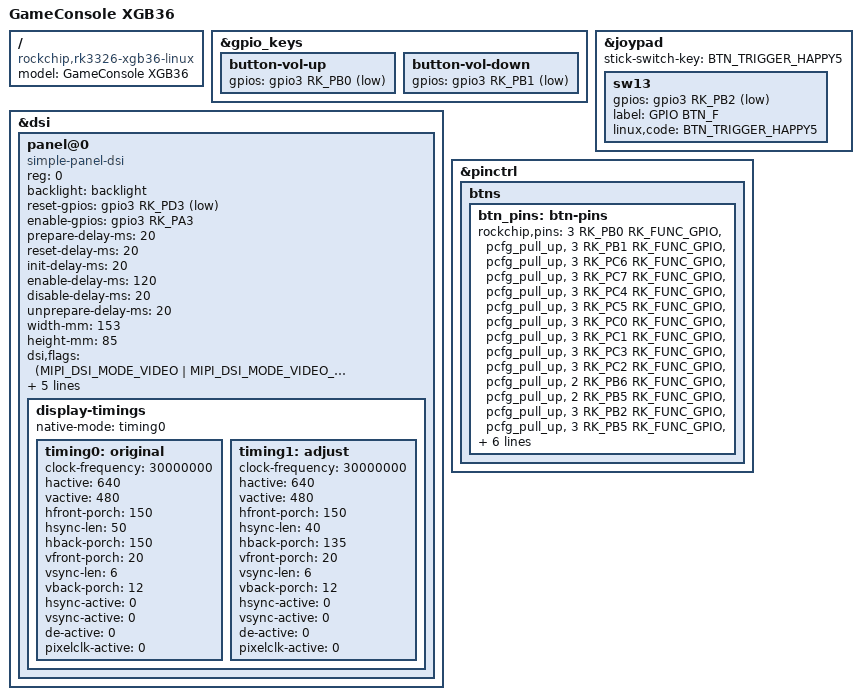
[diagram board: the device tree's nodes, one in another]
// SPDX-License-Identifier: (GPL-2.0+ OR MIT)
/*
* Copyright (c) 2025 kk&lcdyk
*
* GameConsole XGB36
*
*/

/dts-v1/;
#include "rk3326-mymini-linux.dts"

/ {
	model = "GameConsole XGB36";
	compatible = "rockchip,rk3326-xgb36-linux", "rockchip,rk3326";
};

&gpio_keys {
    button-vol-up {
        gpios = <&gpio3 RK_PB0 GPIO_ACTIVE_LOW>;
    };
    button-vol-down {
        gpios = <&gpio3 RK_PB1 GPIO_ACTIVE_LOW>;
    };
};

&joypad {
	stick-switch-key = <BTN_TRIGGER_HAPPY5>;
	sw13 {
		gpios = <&gpio3 RK_PB2 GPIO_ACTIVE_LOW>;
		label = "GPIO BTN_F";
		linux,code = <BTN_TRIGGER_HAPPY5>;
	};
};

&dsi {
	status = "okay";
	
	panel@0 {
		compatible = "simple-panel-dsi";
		reg = <0>;
		/* pwm1 backlight */
		backlight = <&backlight>;
		/* LCD reset gpio GPIO3.D3 */
		reset-gpios = <&gpio3 RK_PD3 GPIO_ACTIVE_LOW>;
		/* power-supply-gpio GPIO3.A3  */
		enable-gpios = <&gpio3 RK_PA3 GPIO_ACTIVE_HIGH>;
		prepare-delay-ms = <20>;
		reset-delay-ms = <20>;
		init-delay-ms = <20>;
		enable-delay-ms = <120>;
		disable-delay-ms = <20>;
		unprepare-delay-ms = <20>;
		width-mm = <153>;
		height-mm = <85>;
		dsi,flags  = <(MIPI_DSI_MODE_VIDEO |
		MIPI_DSI_MODE_VIDEO_BURST |
		MIPI_DSI_MODE_LPM |
		MIPI_DSI_MODE_EOT_PACKET)>;
		dsi,format = <MIPI_DSI_FMT_RGB888>;
		dsi,lanes = <4>;
		panel-init-sequence = [39 00 04 b9 f1 12 83 39 00 06 b1 00 00 00 da 80 39 00 04 b2 00 13 70 39 00 0b b3 10 10 28 28 03 ff 00 00 00 00 15 00 02 b4 80 15 00 03 b5 0a 0a 15 00 03 b6 82 82 39 00 05 b8 26 62 f0 63 39 00 1c ba 33 81 05 f9 0e 0e 20 00 00 00 00 00 00 00 44 25 00 90 0a 00 00 01 4f 01 00 00 37 15 00 02 bc 47 39 00 04 bf 02 11 00 39 00 0a c0 73 73 50 50 00 00 12 50 00 39 00 0d c1 53 00 32 32 77 d1 cc cc 77 77 33 33 39 00 07 c6 82 00 bf ff 00 ff 39 00 07 c7 b8 00 0a 00 00 00 39 00 05 c8 10 40 1e 02 15 00 02 cc 0b 39 00 23 e0 00 07 0d 37 35 3f 41 44 06 0c 0d 0f 11 10 12 14 1a 00 07 0d 37 35 3f 41 44 06 0c 0d 0f 11 10 12 14 1a 39 00 0f e3 07 07 0b 0b 0b 0b 00 00 00 00 ff 00 c0 10 39 00 40 e9 c8 10 02 00 00 b0 b1 11 31 23 28 80 b0 b1 27 08 00 04 02 00 00 00 00 04 02 00 00 00 88 88 ba 60 24 08 88 88 88 88 88 88 88 ba 71 35 18 88 88 88 88 88 00 00 00 01 00 00 00 00 00 00 00 00 00 39 00 3e ea 97 0a 82 02 03 07 00 00 00 00 00 00 81 88 ba 17 53 88 88 88 88 88 88 80 88 ba 06 42 88 88 88 88 88 88 23 00 00 02 80 00 00 00 00 00 00 00 00 00 00 00 00 00 00 00 00 00 00 00 00 00 00 39 00 04 ef ff ff 01 05 c8 01 11 05 14 01 29];
		panel-exit-sequence = <0x5000128 0x5000110>;
		
		display-timings {
			native-mode = <&timing0>;
			
			// 30.00MHz / (640+150+50+150)×(480+20+6+12) = 990×518 = 58.50 Hz
			timing0: original {
				clock-frequency = <30000000>;
				hactive = <640>;
				vactive = <480>;
				hfront-porch = <150>;
				hsync-len = <50>;
				hback-porch = <150>;
				vfront-porch = <20>;
				vsync-len = <6>;
				vback-porch = <12>;
				hsync-active = <0>;
				vsync-active = <0>;
				de-active = <0>;
				pixelclk-active = <0>;
			};
			
			// 30.00MHz / (640+150+40+135)×(480+20+6+12) = 965×518 = 60.02 Hz
			timing1: adjust {
				clock-frequency = <30000000>;
				hactive = <640>;
				vactive = <480>;
				hfront-porch = <150>;
				hsync-len = <40>;
				hback-porch = <135>;
				vfront-porch = <20>;
				vsync-len = <6>;
				vback-porch = <12>;
				hsync-active = <0>;
				vsync-active = <0>;
				de-active = <0>;
				pixelclk-active = <0>;
			};
		};
	};
};

&pinctrl {
	btns {
		btn_pins: btn-pins {
			rockchip,pins =
			<3 RK_PB0 RK_FUNC_GPIO &pcfg_pull_up>,
			<3 RK_PB1 RK_FUNC_GPIO &pcfg_pull_up>,
			<3 RK_PC6 RK_FUNC_GPIO &pcfg_pull_up>,
			<3 RK_PC7 RK_FUNC_GPIO &pcfg_pull_up>,
			<3 RK_PC4 RK_FUNC_GPIO &pcfg_pull_up>,
			<3 RK_PC5 RK_FUNC_GPIO &pcfg_pull_up>,
			<3 RK_PC0 RK_FUNC_GPIO &pcfg_pull_up>,
			<3 RK_PC1 RK_FUNC_GPIO &pcfg_pull_up>,
			<3 RK_PC3 RK_FUNC_GPIO &pcfg_pull_up>,
			<3 RK_PC2 RK_FUNC_GPIO &pcfg_pull_up>,
			<2 RK_PB6 RK_FUNC_GPIO &pcfg_pull_up>,
			<2 RK_PB5 RK_FUNC_GPIO &pcfg_pull_up>,
			<3 RK_PB2 RK_FUNC_GPIO &pcfg_pull_up>,
			<3 RK_PB5 RK_FUNC_GPIO &pcfg_pull_up>,
			<3 RK_PB3 RK_FUNC_GPIO &pcfg_pull_up>,
			<3 RK_PD0 RK_FUNC_GPIO &pcfg_pull_up>,
			<3 RK_PB4 RK_FUNC_GPIO &pcfg_pull_up>,
			<3 RK_PB6 RK_FUNC_GPIO &pcfg_pull_up>,
			<3 RK_PD1 RK_FUNC_GPIO &pcfg_pull_up>;
		};
	};
};

/* DON'T PUT ANYTHING BELOW HERE.  PUT IT ABOVE PINCTRL */

